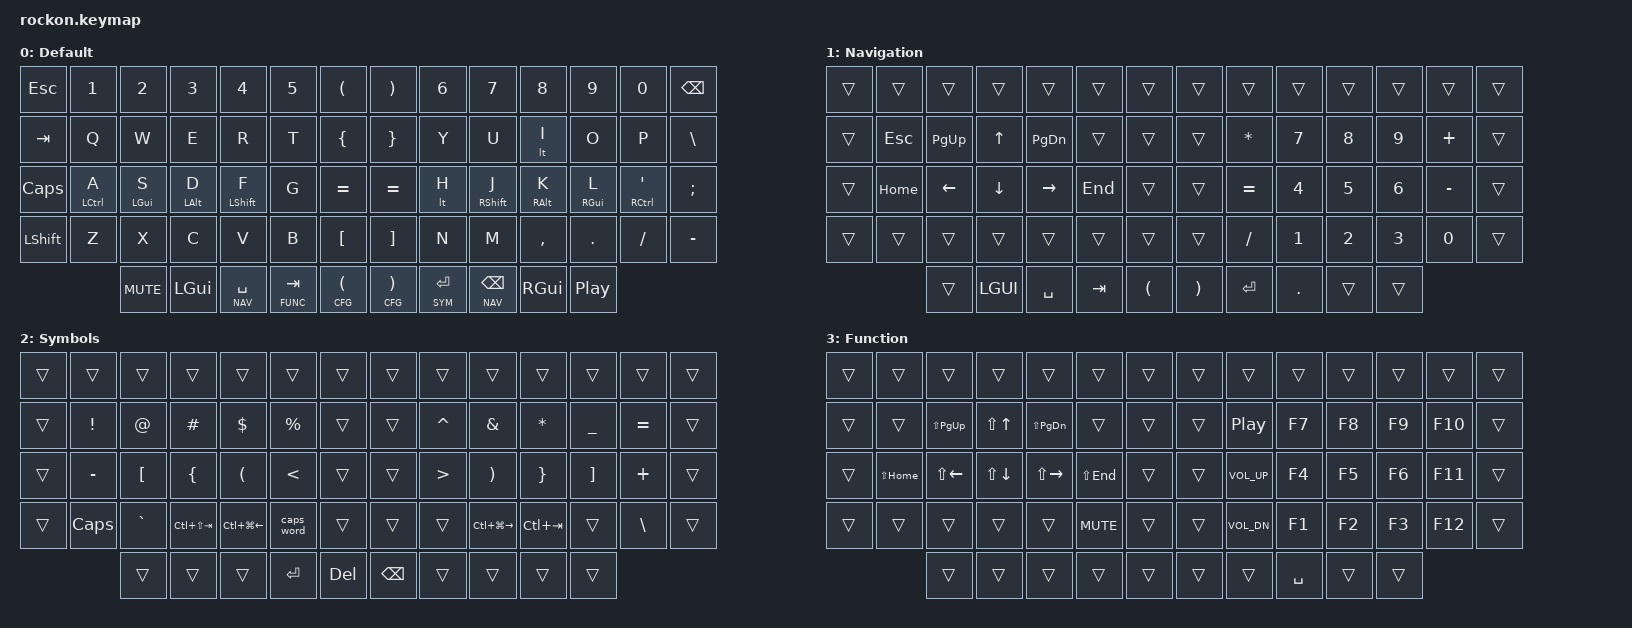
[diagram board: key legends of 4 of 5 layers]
#include <behaviors.dtsi>
#include <dt-bindings/zmk/keys.h>
#include <dt-bindings/zmk/rgb.h>
#include <dt-bindings/zmk/bt.h>
#include <dt-bindings/zmk/ext_power.h>
#include <dt-bindings/zmk/outputs.h>

#define DEFAULT 0
#define NAV     1
#define SYM     2
#define FUNC    3
#define CFG     4

&caps_word {
    continue-list = <UNDERSCORE MINUS>;
};

/ {
    combos {
        compatible = "zmk,combos";
        combo_undo {
            timeout-ms = <50>;
            key-positions = <26 27>;
            bindings = <&kp LC(Z)>;
        };
        combo_q {
            timeout-ms = <50>;
            key-positions = <27 28>;
            bindings = <&kp Q>;
        };
        combo_semicolon {
            timeout-ms = <50>;
            key-positions = <33 34>;
            bindings = <&kp SEMI>;
        };
    };
};

/ {
    behaviors {
        hm: homerow_mods {
            compatible = "zmk,behavior-hold-tap";
            label = "HOMEROW_MODS";
            #binding-cells = <2>;
            tapping-term-ms = <200>;
            quick_tap_ms = <0>;
            flavor = "balanced";
            bindings = <&kp>, <&kp>;
        };
        hs: homerow_shift {
            compatible = "zmk,behavior-hold-tap";
            label = "HOMEROW_SHIFT";
            #binding-cells = <2>;
            tapping-term-ms = <175>;
            quick_tap_ms = <0>;
            flavor = "balanced";
            bindings = <&kp>, <&kp>;
        };
    };

    keymap {
        compatible = "zmk,keymap";

        default_layer {
            label = "Default";
            bindings = <
    &kp ESC    &kp N1      &kp N2      &kp N3      &kp N4        &kp N5        &kp LPAR             &kp RPAR        &kp N6         &kp N7        &kp N8        &kp N9      &kp N0       &kp BSPC
    &kp TAB    &kp Q       &kp W       &kp E       &kp R         &kp T         &kp LBRC             &kp RBRC        &kp Y          &kp U         &lt I         &kp O       &kp P        &kp BSLH
    &kp CAPS   &hm LCTL A  &hm LGUI S  &hm LALT D  &hs LSHIFT F  &kp G         &kp EQUAL            &kp EQUAL       &lt H          &hs RSHIFT J  &hm RALT K    &hm RGUI L  &hm RCTL SQT &kp SCLN
    &kp LSHIFT &kp Z       &kp X       &kp C       &kp V         &kp B         &kp LBKT             &kp RBKT        &kp N          &kp M         &kp COMMA     &kp DOT     &kp FSLH     &kp MINUS
                           &kp C_MUTE  &kp LGUI    &lt NAV SPACE &lt FUNC TAB  &lt CFG LPAR         &lt CFG RPAR    &lt SYM RET    &lt NAV BSPC  &kp RGUI      &kp C_PLAY_PAUSE
            >;
        };

        nav_layer {
            label = "Navigation";
            
            bindings = <
    &trans     &trans       &trans       &trans      &trans        &trans      &trans               &trans          &trans         &trans        &trans        &trans      &trans      &trans
    &trans     &kp ESC      &kp PG_UP    &kp UP      &kp PG_DN     &trans      &trans               &trans          &kp ASTRK      &kp N7        &kp N8        &kp N9      &kp PLUS    &trans
    &trans     &kp HOME     &kp LEFT     &kp DOWN    &kp RIGHT     &kp END     &trans               &trans          &kp EQUAL      &kp N4        &kp N5        &kp N6      &kp MINUS   &trans
    &trans     &trans       &trans       &trans      &trans        &trans      &trans               &trans          &kp FSLH       &kp N1        &kp N2        &kp N3      &kp N0      &trans
                            &trans       &LGUI       &kp SPACE     &kp TAB     &kp LPAR             &kp RPAR        &kp RET        &kp DOT       &trans        &trans
            >;
        };

        sym_layer {
            label = "Symbols";

            bindings = <
    &trans     &trans       &trans       &trans          &trans           &trans        &trans         &trans         &trans        &trans            &trans        &trans      &trans      &trans
    &trans     &kp EXCL     &kp AT       &kp HASH        &kp DLLR         &kp PRCNT     &trans         &trans         &kp CARET     &kp AMPS          &kp ASTRK     &kp UNDER   &kp EQUAL   &trans
    &trans     &kp MINUS    &kp LBKT     &kp LBRC        &kp LPAR         &kp LT        &trans         &trans         &kp GT        &kp RPAR          &kp RBRC      &kp RBKT    &kp PLUS    &trans
    &trans     &kp CAPS     &kp GRAVE    &kp LC(LS(TAB)) &kp LC(LG(LEFT)) &caps_word    &trans         &trans         &trans        &kp LC(LG(RIGHT)) &kp LC(TAB)   &trans      &kp BSLH    &trans
                            &trans       &trans          &trans           &kp RET       &kp DEL        &kp BSPC       &trans        &trans            &trans        &trans
            >;
        };

        func_layer {
            label = "Function";

            bindings = <
    &trans     &trans       &trans        &trans       &trans        &trans        &trans             &trans     &trans           &trans       &trans        &trans      &trans      &trans
    &trans     &trans       &kp LS(PG_UP) &kp LS(UP)   &kp LS(PG_DN) &trans        &trans             &trans     &kp C_PLAY_PAUSE &kp F7       &kp F8        &kp F9      &kp F10     &trans
    &trans     &kp LS(HOME) &kp LS(LEFT)  &kp LS(DOWN) &kp LS(RIGHT) &kp LS(END)   &trans             &trans     &kp K_VOL_UP     &kp F4       &kp F5        &kp F6      &kp F11     &trans
    &trans     &trans       &trans        &trans       &trans        &kp C_MUTE    &trans             &trans     &kp K_VOL_DN     &kp F1       &kp F2        &kp F3      &kp F12     &trans
                            &trans        &trans       &trans        &trans        &trans             &trans     &trans           &kp SPACE    &trans        &trans
            >;
        };

        media_layer {
            label = "Media";

            bindings = <
    &trans                                 &trans           &trans           &trans          &trans            &trans            &trans            &trans     &trans             &trans            &trans             &trans         &trans          &trans
    &rgb_ug RGB_COLOR_HSB(0,0,100)         &rgb_ug RGB_TOG  &rgb_ug RGB_EFR  &rgb_ug RGB_EFF &trans            &trans            &trans            &trans     &bootloader        &bt BT_PRV        &bt BT_NXT         &trans         &trans          &trans
    &rgb_ug RGB_COLOR_HSB(224,100,100)     &trans           &rgb_ug RGB_HUI  &rgb_ug RGB_SAI &rgb_ug RGB_BRI   &rgb_ug RGB_SPI   &trans            &trans     &bt BT_CLR         &bt BT_SEL 0      &bt BT_SEL 1       &bt BT_SEL 2   &bt BT_SEL 3    &trans
    &rgb_ug RGB_COLOR_HSB(278,100,100)     &trans           &rgb_ug RGB_HUD  &rgb_ug RGB_SAD &rgb_ug RGB_BRD   &rgb_ug RGB_SPD   &trans            &trans     &ext_power EP_TOG  &ext_power EP_ON  &ext_power EP_OFF  &out OUT_USB   &out OUT_BLE    &trans
                                                            &trans           &trans          &trans            &trans            &trans            &trans     &trans             &trans            &trans             &trans
            >;
        };
    };
};
